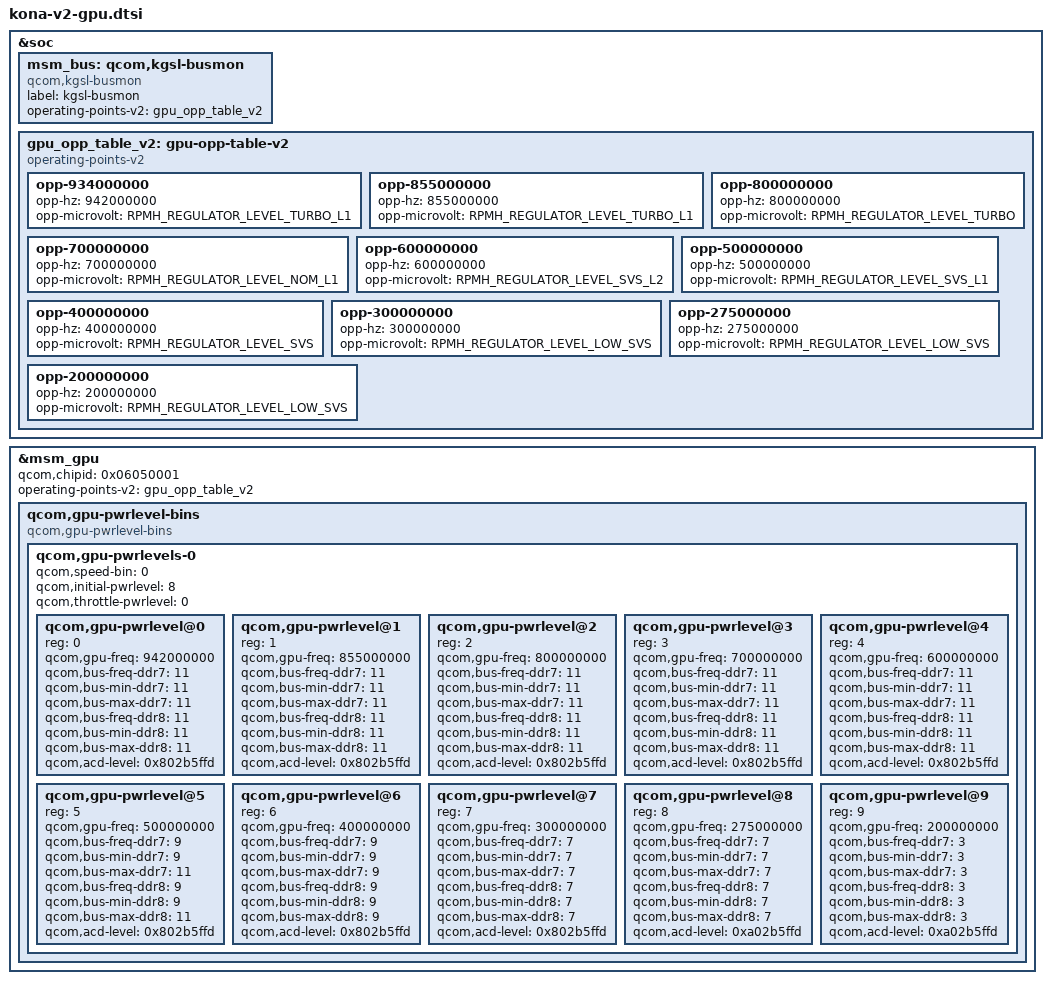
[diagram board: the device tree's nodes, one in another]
&soc {
	msm_bus: qcom,kgsl-busmon {
		label = "kgsl-busmon";
		compatible = "qcom,kgsl-busmon";
		operating-points-v2 = <&gpu_opp_table_v2>;
	};

	gpu_opp_table_v2: gpu-opp-table-v2 {
		compatible = "operating-points-v2";

		opp-934000000 {
			opp-hz = /bits/ 64 <942000000>;
			opp-microvolt = <RPMH_REGULATOR_LEVEL_TURBO_L1>;
		};

		opp-855000000 {
			opp-hz = /bits/ 64 <855000000>;
			opp-microvolt = <RPMH_REGULATOR_LEVEL_TURBO_L1>;
		};

		opp-800000000 {
			opp-hz = /bits/ 64 <800000000>;
			opp-microvolt = <RPMH_REGULATOR_LEVEL_TURBO>;
		};

		opp-700000000 {
			opp-hz = /bits/ 64 <700000000>;
			opp-microvolt = <RPMH_REGULATOR_LEVEL_NOM_L1>;
		};

		opp-600000000 {
			opp-hz = /bits/ 64 <600000000>;
			opp-microvolt = <RPMH_REGULATOR_LEVEL_SVS_L2>;
		};

		opp-500000000 {
			opp-hz = /bits/ 64 <500000000>;
			opp-microvolt = <RPMH_REGULATOR_LEVEL_SVS_L1>;
		};

		opp-400000000 {
			opp-hz = /bits/ 64 <400000000>;
			opp-microvolt = <RPMH_REGULATOR_LEVEL_SVS>;
		};

		opp-300000000 {
			opp-hz = /bits/ 64 <300000000>;
			opp-microvolt = <RPMH_REGULATOR_LEVEL_LOW_SVS>;
		};

		opp-275000000 {
			opp-hz = /bits/ 64 <275000000>;
			opp-microvolt = <RPMH_REGULATOR_LEVEL_LOW_SVS>;
		};

		opp-200000000 {
			opp-hz = /bits/ 64 <200000000>;
			opp-microvolt = <RPMH_REGULATOR_LEVEL_LOW_SVS>;
		};
	};
};

&msm_gpu {
	qcom,chipid = <0x06050001>;

	/* GPU OPP data */
	operating-points-v2 = <&gpu_opp_table_v2>;

	/delete-property/qcom,initial-pwrlevel;
	/delete-node/qcom,gpu-pwrlevels;

	/* Power levels bins */
	qcom,gpu-pwrlevel-bins {
		compatible="qcom,gpu-pwrlevel-bins";
		#address-cells = <1>;
		#size-cells = <0>;

		qcom,gpu-pwrlevels-0 {
			#address-cells = <1>;
			#size-cells = <0>;
			qcom,speed-bin = <0>;
			qcom,initial-pwrlevel = <8>;
			qcom,throttle-pwrlevel = <0>;

			qcom,gpu-pwrlevel@0 {
				reg = <0>;
				qcom,gpu-freq = <942000000>;
				qcom,bus-freq-ddr7 = <11>;
				qcom,bus-min-ddr7 = <11>;
				qcom,bus-max-ddr7 = <11>;

				qcom,bus-freq-ddr8 = <11>;
				qcom,bus-min-ddr8 = <11>;
				qcom,bus-max-ddr8 = <11>;

				qcom,acd-level = <0x802b5ffd>;
			};

			qcom,gpu-pwrlevel@1 {
				reg = <1>;
				qcom,gpu-freq = <855000000>;
				qcom,bus-freq-ddr7 = <11>;
				qcom,bus-min-ddr7 = <11>;
				qcom,bus-max-ddr7 = <11>;

				qcom,bus-freq-ddr8 = <11>;
				qcom,bus-min-ddr8 = <11>;
				qcom,bus-max-ddr8 = <11>;

				qcom,acd-level = <0x802b5ffd>;
			};

			qcom,gpu-pwrlevel@2 {
				reg = <2>;
				qcom,gpu-freq = <800000000>;
				qcom,bus-freq-ddr7 = <11>;
				qcom,bus-min-ddr7 = <11>;
				qcom,bus-max-ddr7 = <11>;

				qcom,bus-freq-ddr8 = <11>;
				qcom,bus-min-ddr8 = <11>;
				qcom,bus-max-ddr8 = <11>;

				qcom,acd-level = <0x802b5ffd>;
			};

			qcom,gpu-pwrlevel@3 {
				reg = <3>;
				qcom,gpu-freq = <700000000>;
				qcom,bus-freq-ddr7 = <11>;
				qcom,bus-min-ddr7 = <11>;
				qcom,bus-max-ddr7 = <11>;

				qcom,bus-freq-ddr8 = <11>;
				qcom,bus-min-ddr8 = <11>;
				qcom,bus-max-ddr8 = <11>;

				qcom,acd-level = <0x802b5ffd>;
			};

			qcom,gpu-pwrlevel@4 {
				reg = <4>;
				qcom,gpu-freq = <600000000>;
				qcom,bus-freq-ddr7 = <11>;
				qcom,bus-min-ddr7 = <11>;
				qcom,bus-max-ddr7 = <11>;

				qcom,bus-freq-ddr8 = <11>;
				qcom,bus-min-ddr8 = <11>;
				qcom,bus-max-ddr8 = <11>;

				qcom,acd-level = <0x802b5ffd>;
			};

			qcom,gpu-pwrlevel@5 {
				reg = <5>;
				qcom,gpu-freq = <500000000>;
				qcom,bus-freq-ddr7 = <9>;
				qcom,bus-min-ddr7 = <9>;
				qcom,bus-max-ddr7 = <11>;

				qcom,bus-freq-ddr8 = <9>;
				qcom,bus-min-ddr8 = <9>;
				qcom,bus-max-ddr8 = <11>;

				qcom,acd-level = <0x802b5ffd>;
			};

			qcom,gpu-pwrlevel@6 {
				reg = <6>;
				qcom,gpu-freq = <400000000>;
				qcom,bus-freq-ddr7 = <9>;
				qcom,bus-min-ddr7 = <9>;
				qcom,bus-max-ddr7 = <9>;

				qcom,bus-freq-ddr8 = <9>;
				qcom,bus-min-ddr8 = <9>;
				qcom,bus-max-ddr8 = <9>;

				qcom,acd-level = <0x802b5ffd>;
			};

			qcom,gpu-pwrlevel@7 {
				reg = <7>;
				qcom,gpu-freq = <300000000>;
				qcom,bus-freq-ddr7 = <7>;
				qcom,bus-min-ddr7 = <7>;
				qcom,bus-max-ddr7 = <7>;

				qcom,bus-freq-ddr8 = <7>;
				qcom,bus-min-ddr8 = <7>;
				qcom,bus-max-ddr8 = <7>;

				qcom,acd-level = <0x802b5ffd>;
			};

			qcom,gpu-pwrlevel@8 {
				reg = <8>;
				qcom,gpu-freq = <275000000>;
				qcom,bus-freq-ddr7 = <7>;
				qcom,bus-min-ddr7 = <7>;
				qcom,bus-max-ddr7 = <7>;

				qcom,bus-freq-ddr8 = <7>;
				qcom,bus-min-ddr8 = <7>;
				qcom,bus-max-ddr8 = <7>;

				qcom,acd-level = <0xa02b5ffd>;
			};

			qcom,gpu-pwrlevel@9 {
				reg = <9>;
				qcom,gpu-freq = <200000000>;
				qcom,bus-freq-ddr7 = <3>;
				qcom,bus-min-ddr7 = <3>;
				qcom,bus-max-ddr7 = <3>;

				qcom,bus-freq-ddr8 = <3>;
				qcom,bus-min-ddr8 = <3>;
				qcom,bus-max-ddr8 = <3>;

				qcom,acd-level = <0xa02b5ffd>;
			};
		};
	};
};
